# SAM9X75D2GN4 register map
Vendor: Microchip Technology; Series: SAM9X7; File version: 0
Registers are 32-bit, read-write, reset 0x0 unless marked. A register's access mark holds for its fields unless they carry their own. Offsets are from the block's base; [hi:lo] are bit positions; {n}, {i} and the like mark numbered series; 'fields as' and 'values as' point back to an identical list.

## RTC — Real-time Clock
Base 0xFFFFFEA8
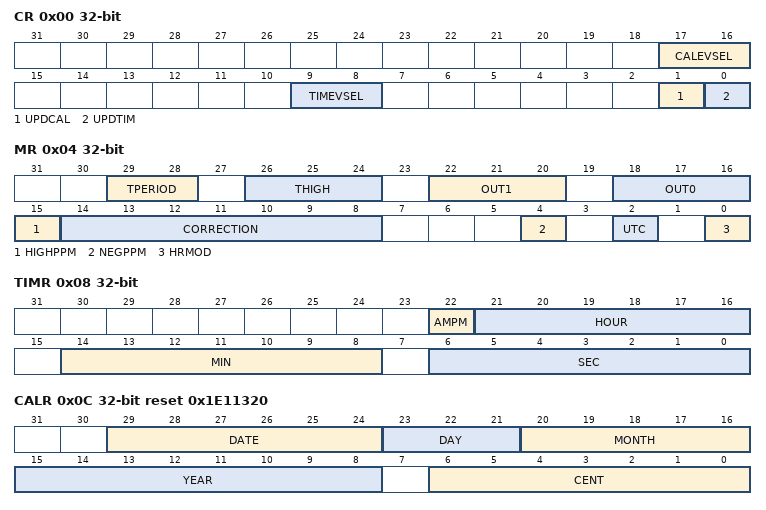
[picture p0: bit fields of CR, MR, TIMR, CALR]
0x00 CR — Control Register
  [17:16] CALEVSEL — Calendar Event Selection
    0=WEEK (Week change (every Monday at time 00:00:00)); 1=MONTH (Month change (every 01 of each month at time 00:00:00)); 2=YEAR (Year change (every January 1 at time 00:00:00))
  [9:8] TIMEVSEL — Time Event Selection
    0=MINUTE (Minute change); 1=HOUR (Hour change); 2=MIDNIGHT (Every day at midnight); 3=NOON (Every day at noon)
  [1] UPDCAL — Update Request Calendar Register
    0=CLOSE_UPDATE (No effect or, if UPDCAL has been previously written to 1, stops the update procedure.); 1=START_UPDATE (Stops the RTC calendar counting.)
  [0] UPDTIM — Update Request Time Register
    0=CLOSE_UPDATE (No effect or, if UPDTIM has been previously written to 1, stops the update procedure.); 1=START_UPDATE (Stops the RTC time counting.)
0x04 MR — Mode Register
  [29:28] TPERIOD — Period of the Output Pulse
    0=P_1S (1 second); 1=P_500MS (500 ms); 2=P_250MS (250 ms); 3=P_125MS (125 ms)
  [26:24] THIGH — High Duration of the Output Pulse
    0=H_31MS (31.2 ms); 1=H_16MS (15.6 ms); 2=H_4MS (3.91 ms); 3=H_976US (976 us); 4=H_488US (488 us); 5=H_122US (122 us); 6=H_30US (30.5 us); 7=H_15US (15.2 us)
  [22:20] OUT1 — ADC Last Channel Trigger Event Source Selection
    0=NO_WAVE (No waveform, stuck at '0'); 1=FREQ1HZ (1 Hz square wave); 2=FREQ32HZ (32 Hz square wave); 3=FREQ64HZ (64 Hz square wave); 4=FREQ512HZ (512 Hz square wave); 5=ALARM_TOGGLE (Output toggles when alarm flag rises); 6=ALARM_FLAG (Output is a copy of the alarm flag); 7=PROG_PULSE (Duty cycle programmable pulse)
  [18:16] OUT0 — All ADC Channel Trigger Event Source Selection
    values as OUT1
  [15] HIGHPPM — HIGH PPM Correction
    0=DISABLED (Lower range ppm correction with accurate correction (below 30 ppm ocrrection).); 1=ENABLED (Higher range ppm correction with accurate correction (higher than 30 ppm correction).)
  [14:8] CORRECTION — Slow Clock Correction
    0=DISABLED (No correction)
  [4] NEGPPM — NEGative PPM Correction
    0=DISABLED (Positive correction (the divider will be slightly higher than 32768).); 1=ENABLED (Negative correction (the divider will be slightly lower than 32768).)
  [2] UTC — UTC Time Format
    0=DISABLED (Gregorian calendar.); 1=ENABLED (UTC format.)
  [0] HRMOD — 12-/24-hour Mode
    0=24HOURS (24-hour mode is selected.); 1=AMPM (12-hour mode is selected.)
0x08 TIMR — Time Register
  [22] AMPM — Ante Meridiem Post Meridiem Indicator
    0=AM; 1=PM
  [21:16] HOUR — Current Hour
  [14:8] MIN — Current Minute
  [6:0] SEC — Current Second
0x08 TIMR_UTC_MODE (alternate view of TIMR) — Time Register
  [31:0] UTC_TIME — Current UTC Time
0x0C CALR reset 0x1E11320 — Calendar Register
  [29:24] DATE — Current Day in Current Month
  [23:21] DAY — Current Day in Current Week
  [20:16] MONTH — Current Month
  [15:8] YEAR — Current Year
  [6:0] CENT — Current Century
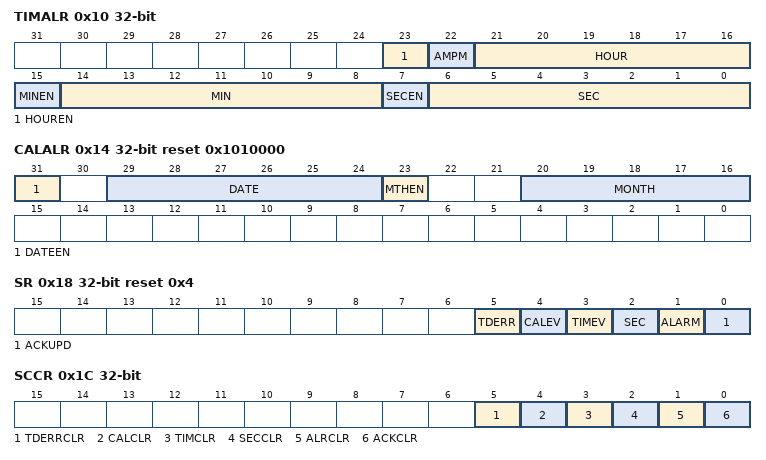
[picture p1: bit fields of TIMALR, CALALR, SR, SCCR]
0x10 TIMALR — Time Alarm Register
  [23] HOUREN — Hour Alarm Enable
    0=DISABLED (The hour-matching alarm is disabled.); 1=ENABLED (The hour-matching alarm is enabled.)
  [22] AMPM — AM/PM Indicator
  [21:16] HOUR — Hour Alarm
  [15] MINEN — Minute Alarm Enable
    0=DISABLED (The minute-matching alarm is disabled.); 1=ENABLED (The minute-matching alarm is enabled.)
  [14:8] MIN — Minute Alarm
  [7] SECEN — Second Alarm Enable
    0=DISABLED (The second-matching alarm is disabled.); 1=ENABLED (The second-matching alarm is enabled.)
  [6:0] SEC — Second Alarm
0x10 TIMALR_UTC_MODE (alternate view of TIMALR) — Time Alarm Register
  [31:0] UTC_TIME — UTC_TIME Alarm
    1=Disable the UTC alarm by clearing the UTCEN bit in RTC_CALALR if it is not already cleared; 2=Change the UTC_TIME alarm value; 3=Enable the UTC alarm by setting the UTCEN bit in RTC_CALALR
0x14 CALALR reset 0x1010000 — Calendar Alarm Register
  [31] DATEEN — Date Alarm Enable
    0=DISABLED (The date-matching alarm is disabled.); 1=ENABLED (The date-matching alarm is enabled.)
  [29:24] DATE — Date Alarm
  [23] MTHEN — Month Alarm Enable
    0=DISABLED (The month-matching alarm is disabled.); 1=ENABLED (The month-matching alarm is enabled.)
  [20:16] MONTH — Month Alarm
0x14 CALALR_UTC_MODE reset 0x1010000 (alternate view of CALALR) — Calendar Alarm Register
  [0] UTCEN — UTC Alarm Enable
    0=DISABLED (The UTC-matching alarm is disabled.); 1=ENABLED (The UTC-matching alarm is enabled.)
0x18 SR ro reset 0x4 — Status Register
  [5] TDERR — Time and/or Date Free Running Error
    0=CORRECT (The internal free running counters are carrying valid values since the last read of the Status Register (RTC_SR).); 1=ERR_TIMEDATE (The internal free running counters have been corrupted (invalid date or time, non-BCD values) since the last read and/or they are still invalid.)
  [4] CALEV — Calendar Event
    0=NO_CALEVENT (No calendar event has occurred since the last clear.); 1=CALEVENT (At least one calendar event has occurred since the last clear.)
  [3] TIMEV — Time Event
    0=NO_TIMEVENT (No time event has occurred since the last clear.); 1=TIMEVENT (At least one time event has occurred since the last clear.)
  [2] SEC — Second Event
    0=NO_SECEVENT (No second event has occurred since the last clear.); 1=SECEVENT (At least one second event has occurred since the last clear.)
  [1] ALARM — Alarm Flag
    0=NO_ALARMEVENT (No alarm matching condition occurred.); 1=ALARMEVENT (An alarm matching condition has occurred.)
  [0] ACKUPD — Acknowledge for Update
    0=FREERUN (Time and calendar registers cannot be updated.); 1=UPDATE (Time and calendar registers can be updated.)
0x1C SCCR wo — Status Clear Command Register
  [5] TDERRCLR — Time and/or Date Free Running Error Clear
  [4] CALCLR — Calendar Clear
  [3] TIMCLR — Time Clear
  [2] SECCLR — Second Clear
  [1] ALRCLR — Alarm Clear
  [0] ACKCLR — Acknowledge Clear
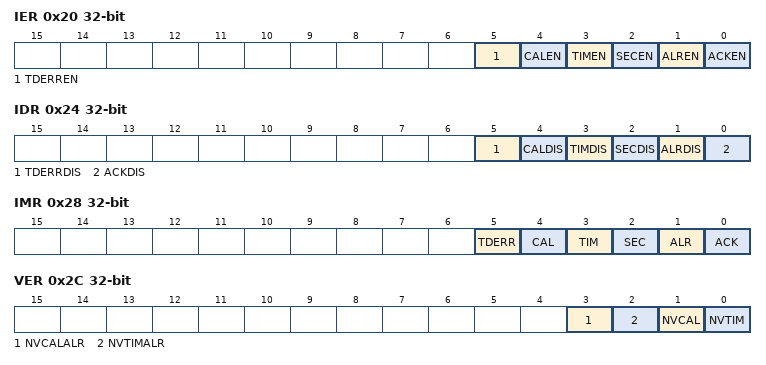
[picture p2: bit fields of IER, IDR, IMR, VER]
0x20 IER wo — Interrupt Enable Register
  [5] TDERREN — Time and/or Date Error Interrupt Enable
  [4] CALEN — Calendar Event Interrupt Enable
  [3] TIMEN — Time Event Interrupt Enable
  [2] SECEN — Second Event Interrupt Enable
  [1] ALREN — Alarm Interrupt Enable
  [0] ACKEN — Acknowledge Update Interrupt Enable
0x24 IDR wo — Interrupt Disable Register
  [5] TDERRDIS — Time and/or Date Error Interrupt Disable
  [4] CALDIS — Calendar Event Interrupt Disable
  [3] TIMDIS — Time Event Interrupt Disable
  [2] SECDIS — Second Event Interrupt Disable
  [1] ALRDIS — Alarm Interrupt Disable
  [0] ACKDIS — Acknowledge Update Interrupt Disable
0x28 IMR ro — Interrupt Mask Register
  [5] TDERR — Time and/or Date Error Mask
  [4] CAL — Calendar Event Interrupt Mask
  [3] TIM — Time Event Interrupt Mask
  [2] SEC — Second Event Interrupt Mask
  [1] ALR — Alarm Interrupt Mask
  [0] ACK — Acknowledge Update Interrupt Mask
0x2C VER ro — Valid Entry Register
  [3] NVCALALR — Non-valid Calendar Alarm
    0=No invalid data has been detected in RTC_CALALR (Calendar Alarm register); 1=RTC_CALALR has contained invalid data since it was last programmed
  [2] NVTIMALR — Non-valid Time Alarm
    0=No invalid data has been detected in RTC_TIMALR (Time Alarm register); 1=RTC_TIMALR has contained invalid data since it was last programmed
  [1] NVCAL — Non-valid Calendar
    0=No invalid data has been detected in RTC_CALR (Calendar register); 1=RTC_CALR has contained invalid data since it was last programmed
  [0] NVTIM — Non-valid Time
    0=No invalid data has been detected in RTC_TIMR (Time register); 1=RTC_TIMR has contained invalid data since it was last programmed
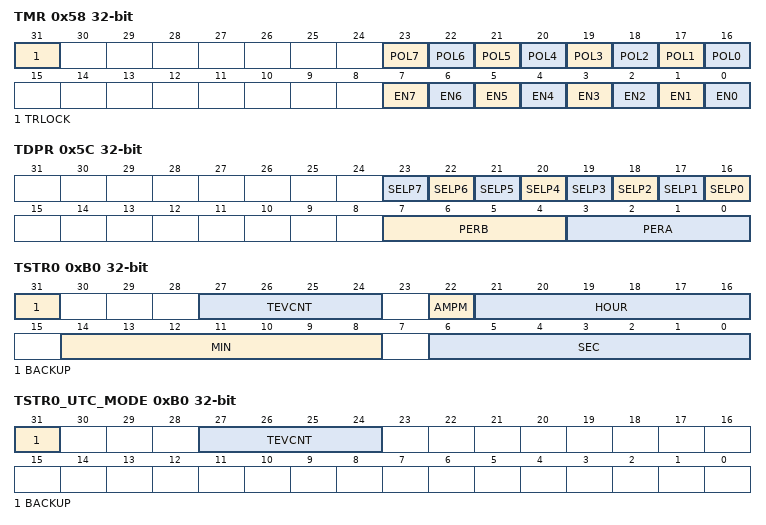
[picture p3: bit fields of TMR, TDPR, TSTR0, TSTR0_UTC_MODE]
0x58 TMR — Tamper Mode Register
  [31] TRLOCK — Tamper Registers Lock (Write-once, cleared by VDDCORE reset)
    0=UNLOCKED (RTC_TMR and RTC_TDPR can be written.); 1=LOCKED (RTC_TMR and RTC_TDPR cannot be written until the next VDDCORE domain reset.)
  [n+16] POL{n} (n=0..7) — WKUPx+1 Polarity
    0=LOW (If the source of tamper remains low for a debounce period, a tamper event is generated.); 1=HIGH (If the source of tamper remains high for a debounce period, a tamper event is generated.)
  [n] EN{n} (n=0..7) — WKUPx+1 Tamper Source Enable
    0=DISABLE (WKUP pin index x+1 is not enabled as a source of tamper.); 1=ENABLE (WKUP pin index x+1 is enabled as a source of tamper.)
0x5C TDPR — Tamper Debounce Period register
  [n+16] SELP{n} (n=0..7) — WKUPx+1 Debounce Period Selection
    0=SEL_PA (WKUP pin index x+1 is debounced with PERA period.); 1=SEL_PB (WKUP pin index x+1 is debounced with PERB period.)
  [7:4] PERB — Debounce Period B
    0=MD_SLCK_2 (The source of tamper must remain active for at least 2 monitoring domain slow clock cycles to generate a tamper event.); 1=MD_SLCK_4 (The source of tamper must remain active for at least 4 monitoring domain slow clock cycles to generate a tamper event.); 2=MD_SLCK_8 (The source of tamper must remain active for at least 8 monitoring domain slow clock cycles to generate a tamper event.); 3=MD_SLCK_16 (The source of tamper must remain active for at least 16 monitoring domain slow clock cycles to generate a tamper event.); 4=MD_SLCK_32 (The source of tamper must remain active for at least 32 monitoring domain slow clock cycles to generate a tamper event.); 5=MD_SLCK_64 (The source of tamper must remain active for at least 64 monitoring domain slow clock cycles to generate a tamper event.); 6=MD_SLCK_128 (The source of tamper must remain active for at least 128 monitoring domain slow clock cycles to generate a tamper event.); 7=MD_SLCK_256 (The source of tamper must remain active for at least 256 monitoring domain slow clock cycles to generate a tamper event.)
  [3:0] PERA — Debounce Period A
    values as PERB
0xB0 TSTR0 ro — Timestamp Time Register 0
  [31] BACKUP — System Mode of the Tamper (cleared by reading RTC_TSSR0)
    0=The state of the system is different from backup mode when the tamper event occurs; 1=The system is in backup mode when the tamper event occurs
  [27:24] TEVCNT — Tamper Events Counter (cleared by reading RTC_TSSR0)
  [22] AMPM — AM/PM Indicator of the Tamper (cleared by reading RTC_TSSR0)
  [21:16] HOUR — Hours of the Tamper (cleared by reading RTC_TSSR0)
  [14:8] MIN — Minutes of the Tamper (cleared by reading RTC_TSSR0)
  [6:0] SEC — Seconds of the Tamper (cleared by reading RTC_TSSR0)
0xB0 TSTR0_UTC_MODE ro (alternate view of TSTR0) — Timestamp Time Register 0
  [31] BACKUP — System Mode of the Tamper (cleared by reading RTC_TSSR0)
    0=The state of the system is different from Backup mode when the tamper event occurs; 1=The system is in Backup mode when the tamper event occurs
  [27:24] TEVCNT — Tamper Events Counter (cleared by reading RTC_TSSR0)
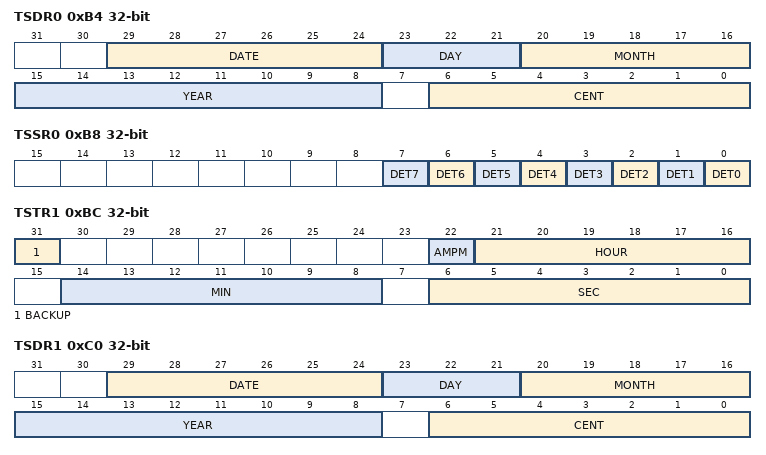
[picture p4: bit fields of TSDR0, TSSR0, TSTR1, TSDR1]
0xB4 TSDR0 ro — Timestamp Date Register 0
  [29:24] DATE — Date of the Tamper (cleared by reading RTC_TSSRx)
  [23:21] DAY — Day of the Tamper (cleared by reading RTC_TSSRx)
  [20:16] MONTH — Month of the Tamper (cleared by reading RTC_TSSRx)
  [15:8] YEAR — Year of the Tamper (cleared by reading RTC_TSSRx)
  [6:0] CENT — Century of the Tamper (cleared by reading RTC_TSSRx)
0xB4 TSDR0_UTC_MODE ro (alternate view of TSDR0) — Timestamp Date Register 0
  [31:0] UTC_TIME — Time of the Tamper (UTC format)
0xB8 TSSR0 ro — Timestamp Source Register 0
  [n] DET{n} (n=0..7) — Tamper Detection on VDDCORE WKUP[8:1] (cleared on read)
0xBC TSTR1 ro — Timestamp Time Register 1
  [31] BACKUP — System Mode of the Tamper (cleared by reading RTC_TSSR1)
    values as TSTR0_UTC_MODE.BACKUP
  [22] AMPM — AM/PM Indicator of the Tamper (cleared by reading RTC_TSSR1)
  [21:16] HOUR — Hours of the Tamper (cleared by reading RTC_TSSR1)
  [14:8] MIN — Minutes of the Tamper (cleared by reading RTC_TSSR1)
  [6:0] SEC — Seconds of the Tamper (cleared by reading RTC_TSSR1)
0xBC TSTR1_UTC_MODE ro (alternate view of TSTR1) — Timestamp Time Register 1
  [31] BACKUP — System Mode of the Tamper (cleared by reading RTC_TSSR1)
    values as TSTR0_UTC_MODE.BACKUP
0xC0 TSDR1 ro — Timestamp Date Register 1
  fields as TSDR0
0xC0 TSDR1_UTC_MODE ro (alternate view of TSDR1) — Timestamp Date Register 1
  [31:0] UTC_TIME — Time of the Tamper (UTC format)
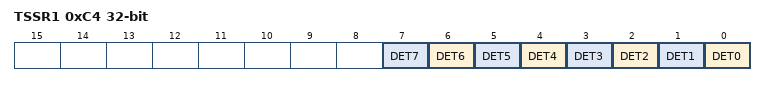
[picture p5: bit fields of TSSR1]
0xC4 TSSR1 ro — Timestamp Source Register 1
  fields as TSSR0

## Notices in the file
Copyright (c) 2026 Microchip Technology Inc.
SPDX-License-Identifier: Apache-2.0
Licensed under the Apache License, Version 2.0 (the "License");
you may not use this file except in compliance with the License.
You may obtain a copy of the License at
http://www.apache.org/licenses/LICENSE-2.0
Unless required by applicable law or agreed to in writing, software
distributed under the License is distributed on an "AS IS" BASIS,
WITHOUT WARRANTIES OR CONDITIONS OF ANY KIND, either express or implied.
See the License for the specific language governing permissions and
limitations under the License.
